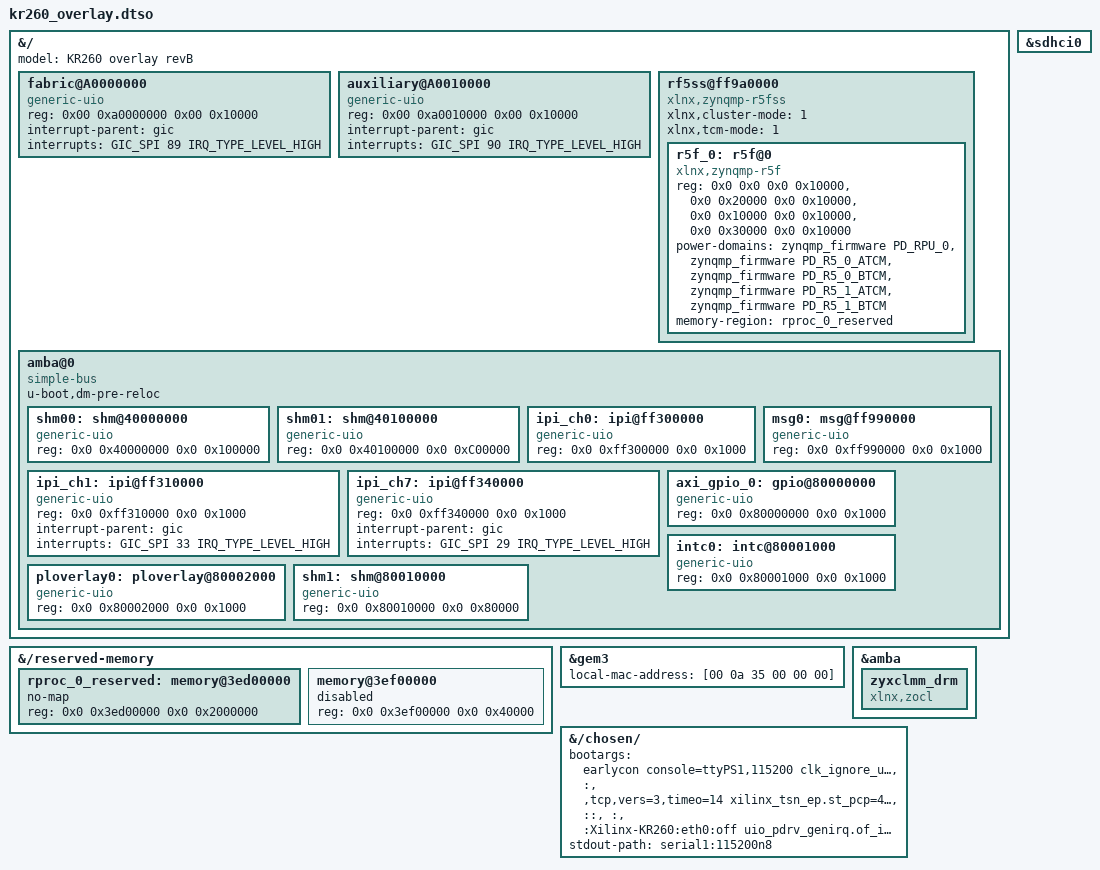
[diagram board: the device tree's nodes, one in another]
/*
 * dts file for KR260 Carrier Card
 *
 * (C) Copyright 2025, Tagus.
 *
 * William Stanislaus <wstanislaus@gmail.com>
 */

#include <dt-bindings/interrupt-controller/arm-gic.h>
#include <dt-bindings/power/xlnx-zynqmp-power.h>

/dts-v1/;
/plugin/;

/* Helper macros to build bootargs string */
#define STRINGIFY(x) #x
#define XSTRINGIFY(x) STRINGIFY(x)

&{/} {
	model = "KR260 overlay revB";
	#address-cells = <2>;
	#size-cells = <2>;

    fabric@A0000000 {
		compatible = "generic-uio";
		reg = <0x00 0xa0000000 0x00 0x10000>;
		interrupt-parent = <&gic>;
		interrupts = <GIC_SPI 89 IRQ_TYPE_LEVEL_HIGH>;
	};
	auxiliary@A0010000 {
		compatible = "generic-uio";
		reg = <0x00 0xa0010000 0x00 0x10000>;
		interrupt-parent = <&gic>;
		interrupts = <GIC_SPI 90 IRQ_TYPE_LEVEL_HIGH>;
	};

	/*
	 * RPU (Real-Time Processing Unit) Configuration
	 *
	 * This node configures the R5F subsystem for remoteproc support, allowing
	 * the APU (Application Processing Unit) to load firmware and start the RPU
	 * cores dynamically. The remoteproc framework in Linux uses this configuration
	 * to manage the RPU lifecycle (load firmware, start, stop, reset).
	 *
	 * Configuration:
	 * - cluster-mode = 1: Split mode (R5F cores operate independently)
	 * - tcm-mode = 1: Split TCM mode (each core has its own TCM)
	 *
	 * The memory-region property references rproc_0_reserved, which provides
	 * a 32MB reserved memory region (0x3ed00000-0x3ed00000+32MB) for firmware
	 * loading and RPU execution.
	 */
	rf5ss@ff9a0000 {
		compatible = "xlnx,zynqmp-r5fss";
		xlnx,cluster-mode = <1>;
		xlnx,tcm-mode = <1>;

		#address-cells = <2>;
		#size-cells = <2>;

		ranges =
			<0x0 0x0      0x0 0xFFE00000 0x0 0x10000>,  // ATCM0
			<0x0 0x20000  0x0 0xFFE20000 0x0 0x10000>,  // BTCM0
			<0x0 0x10000  0x0 0xFFE10000 0x0 0x10000>,  // ATCM1
			<0x0 0x30000  0x0 0xFFE30000 0x0 0x10000>;  // BTCM1

		r5f_0: r5f@0 {
			compatible = "xlnx,zynqmp-r5f";

			#address-cells = <2>;
			#size-cells = <2>;

			reg =
				<0x0 0x0      0x0 0x10000>,   // ATCM0
				<0x0 0x20000  0x0 0x10000>,   // BTCM0
				<0x0 0x10000  0x0 0x10000>,   // ATCM1
				<0x0 0x30000  0x0 0x10000>;   // BTCM1

			reg-names = "atcm0", "btcm0", "atcm1", "btcm1";

			power-domains =
				<&zynqmp_firmware PD_RPU_0>,
				<&zynqmp_firmware PD_R5_0_ATCM>,
				<&zynqmp_firmware PD_R5_0_BTCM>,
				<&zynqmp_firmware PD_R5_1_ATCM>,
				<&zynqmp_firmware PD_R5_1_BTCM>;

			memory-region = <&rproc_0_reserved>;
		};
	};

    /*
     * PL (Programmable Logic) and RPU Communication Infrastructure
     *
     * This amba bus node provides the communication and memory mapping infrastructure
     * for interaction between APU, RPU, and PL (FPGA fabric):
     *
     * 1. Shared Memory Regions:
     *    - shm0 (0x3ed80000, 16MB): APU-RPU shared memory for data exchange
     *    - shm1 (0x80010000, 512KB): Shared memory with PL BRAM for PL-RPU communication
     *
     * 2. Inter-Processor Interrupt (IPI) Channels:
     *    - ipi_ch0 (0xff300000): IPI channel 0 (APU side) for triggering interrupts
     *    - ipi_ch1 (0xff310000): IPI channel 1 (RPU0 side) with interrupt support (GIC SPI 33, ID 65)
     *      This is the primary channel for APU-to-RPU0 communication
     *    - ipi_ch7 (0xff340000): IPI channel 7 (PL1 side) with interrupt support (GIC SPI 29, ID 61)
     *      Channel for PL-to-RPU communication
     *
     * 3. Message Passing:
     *    - msg0 (0xff990000): APU to RPU0 message passing interface for command/acknowledgment handshake
     *
     * 4. PL Overlay Support:
     *    - ploverlay0 (0x80000000): PL overlay control register for dynamic
     *      reconfiguration and PL-RPU interaction
     *    - intc0 (0x80001000): AXI Interrupt Controller for PL-generated interrupts
     *      to APU/RPU
     *
     * All these devices are exposed as generic-uio devices, allowing user-space
     * applications to directly access hardware registers and shared memory regions
     * for low-latency communication between processing units.
     */
    amba@0 {
        compatible = "simple-bus";
        u-boot,dm-pre-reloc;
        #address-cells = <0x2>;
        #size-cells = <0x2>;
        ranges = <0x0 0x0 0x0 0x0 0x1 0x0>;
        /* Shared memory for APU-RPU communication */
        /* Moved to 0x40000000 (19MB offset from 0x3ED00000) to allow large RPU firmware (up to 19MB) */
        shm00: shm@40000000 {
            compatible = "generic-uio";
            reg = <0x0 0x40000000 0x0 0x100000>; /* Reduced to 1MB, fits within 32MB reserved region */
        };

        /* Additional 12MB shared memory from 20MB offset to end of 32MB region */
        shm01: shm@40100000 {
            compatible = "generic-uio";
            reg = <0x0 0x40100000 0x0 0xC00000>;
        };
        /* Inter-Processor Interrupt channel 0 (APU side) */
        ipi_ch0: ipi@ff300000 {
            compatible = "generic-uio";
            reg = <0x0 0xff300000 0x0 0x1000>;
        };
        /* Inter-Processor Interrupt channel 1 (RPU0 side) - APU to RPU0 communication
         * Standard ZynqMP mapping: GIC_SPI 33 (interrupt ID 65)
         * This is the primary IPI channel for APU-RPU0 communication
         */
        ipi_ch1: ipi@ff310000 {
            compatible = "generic-uio";
            reg = <0x0 0xff310000 0x0 0x1000>;
            interrupt-parent = <&gic>;
            interrupts = <GIC_SPI 33 IRQ_TYPE_LEVEL_HIGH>;
        };
        /* Inter-Processor Interrupt channel 7 (PL1 side) - For PL communication
         * This channel can be used for PL-to-RPU communication
         */
        ipi_ch7: ipi@ff340000 {
            compatible = "generic-uio";
            reg = <0x0 0xff340000 0x0 0x1000>;
            interrupt-parent = <&gic>;
            interrupts = <GIC_SPI 29 IRQ_TYPE_LEVEL_HIGH>;
        };
        /* APU to RPU0 message passing interface
         * Shared memory region for command/acknowledgment handshake
         */
        msg0: msg@ff990000 {
            compatible = "generic-uio";
            reg = <0x0 0xff990000 0x0 0x1000>;
        };

        /* AXI GPIO for LED Control (Accessed by RPU) */
        /* Reduced to 4KB to allow space for other peripherals */
        axi_gpio_0: gpio@80000000 {
            compatible = "generic-uio";
            reg = <0x0 0x80000000 0x0 0x1000>;
        };

        /* AXI Interrupt Controller for PL-generated interrupts */
        intc0: intc@80001000 {
            compatible = "generic-uio";
            reg = <0x0 0x80001000 0x0 0x1000>;
        };

        /* PL overlay control register for dynamic reconfiguration */
        ploverlay0: ploverlay@80002000 {
            compatible = "generic-uio";
            reg = <0x0 0x80002000 0x0 0x1000>;
        };

        /* Shared memory with PL BRAM for PL-RPU communication */
        shm1: shm@80010000 {
            compatible = "generic-uio";
            reg = <0x0 0x80010000 0x0 0x80000>;
        };
    };

};

&{/reserved-memory} {
    #address-cells = <2>;
    #size-cells = <2>;
    /*
     * Reserved memory region for RPU firmware loading and execution
     *
     * This 32MB region (0x3ed00000 - 0x3ef00000) is reserved for the remoteproc
     * framework to load RPU firmware images. The remoteproc driver uses this
     * memory to store firmware binaries and provide execution space for the RPU
     * cores. The no-map property ensures this memory is not accessible from the
     * Linux kernel's normal memory management, preventing conflicts.
     */
    rproc_0_reserved: memory@3ed00000 {
            no-map;
            reg = <0x0 0x3ed00000 0x0 0x2000000>;
    };

    /* Disable rproc_1_fw_image from zynqmp.dtsi (RPU core 2, not used) */
    /* Access by node name/address as base DTB symbols might not be available */
    memory@3ef00000 {
            reg = <0x0 0x3ef00000 0x0 0x40000>;
            status = "disabled";
    };
};

&sdhci0 { /* 16GB emmc in production SOM */
	status = "okay";
};

&gem3 {
	local-mac-address = [00 0a 35 00 00 00];
};

&amba {
	zyxclmm_drm {
		compatible = "xlnx,zocl";
		status = "okay";
	};
};

&{/chosen/} {
    bootargs = "earlycon console=ttyPS1,115200 clk_ignore_unused root=/dev/nfs rw nfsroot=" XSTRINGIFY(NFS_SERVER) ":" XSTRINGIFY(NFS_ROOT) ",tcp,vers=3,timeo=14 xilinx_tsn_ep.st_pcp=4 cma=900M ip=" XSTRINGIFY(BOARD_IP) "::" XSTRINGIFY(BOARD_GATEWAY) ":" XSTRINGIFY(BOARD_NETMASK) ":Xilinx-KR260:eth0:off uio_pdrv_genirq.of_id=generic-uio";
    /* bootargs = "earlycon console=ttyPS1,115200 clk_ignore_unused root=/dev/mmcblk0p2 rw rootwait xilinx_tsn_ep.st_pcp=4 cma=900M uio_pdrv_genirq.of_id=generic-uio"; */
    stdout-path = "serial1:115200n8";
};
